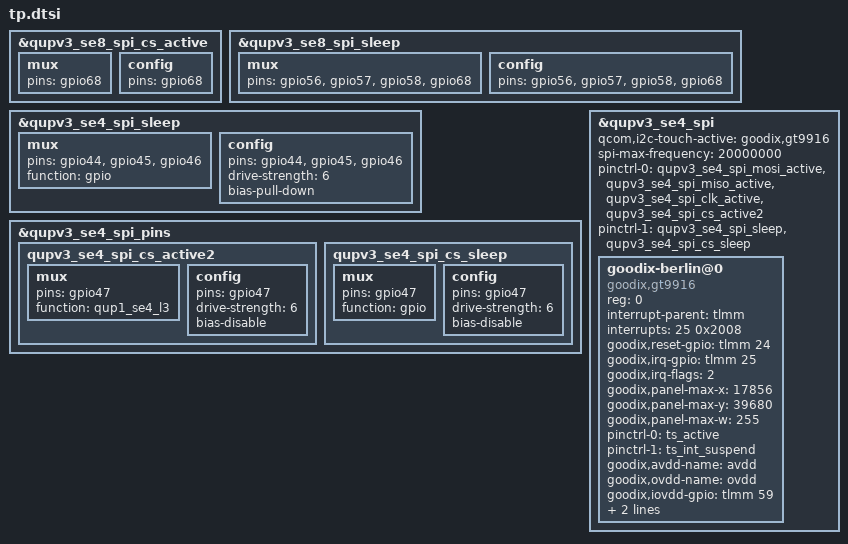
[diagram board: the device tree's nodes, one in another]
&qupv3_se8_spi_cs_active {
	mux {
		pins = "gpio68";
	};

	config {
		pins = "gpio68";
	};
};

&qupv3_se8_spi_sleep {
	mux {
		pins = "gpio56", "gpio57",
			"gpio58", "gpio68";
	};

	config {
		pins = "gpio56", "gpio57",
			"gpio58", "gpio68";
	};
};

&qupv3_se4_spi_sleep {
    mux {
        pins = "gpio44", "gpio45",
            "gpio46";
        function = "gpio";
    };

    config {
        pins = "gpio44", "gpio45",
            "gpio46";
        drive-strength = <6>;
        bias-pull-down;
    };
};

&qupv3_se4_spi_pins {
    qupv3_se4_spi_cs_active2: qupv3_se4_spi_cs_active2 {
        mux {
            pins = "gpio47";
            function = "qup1_se4_l3";
        };

        config {
            pins = "gpio47";
            drive-strength = <6>;
            bias-disable;
        };
    };

    qupv3_se4_spi_cs_sleep: qupv3_se4_spi_cs_sleep {
        mux {
            pins = "gpio47";
            function = "gpio";
        };

        config {
            pins = "gpio47";
            drive-strength = <6>;
            bias-disable;
        };
    };
};

&qupv3_se4_spi {
	#address-cells = <1>;
	#size-cells = <0>;
	status = "ok";
	qcom,i2c-touch-active = "goodix,gt9916";
	spi-max-frequency = <20000000>;
	pinctrl-0 = <&qupv3_se4_spi_mosi_active>, <&qupv3_se4_spi_miso_active>,
		<&qupv3_se4_spi_clk_active>, <&qupv3_se4_spi_cs_active2>;
	pinctrl-1 = <&qupv3_se4_spi_sleep>, <&qupv3_se4_spi_cs_sleep>;
	goodix-berlin@0 {
		compatible = "goodix,gt9916";
		reg = <0>;
		interrupt-parent = <&tlmm>;
		interrupts = <25 0x2008>;
		goodix,reset-gpio = <&tlmm 24 0x00>;
		goodix,irq-gpio = <&tlmm 25 0x2008>;
		goodix,irq-flags = <2>;
		goodix,panel-max-x = <17856>; // 1X:1116, 16X:17856
		goodix,panel-max-y = <39680>; // 1X:2480, 16X:39680
		goodix,panel-max-w = <255>;
		pinctrl-names = "pmx_ts_active","pmx_ts_suspend";
		pinctrl-0 = <&ts_active>;
		pinctrl-1 = <&ts_int_suspend>;
		goodix,avdd-name = "avdd";
		goodix,ovdd-name = "ovdd";
		goodix,iovdd-gpio =<&tlmm 59 0x00>;
		avdd-supply = <&L14B>;
		ovdd-supply = <&BOB2>;
	};
};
